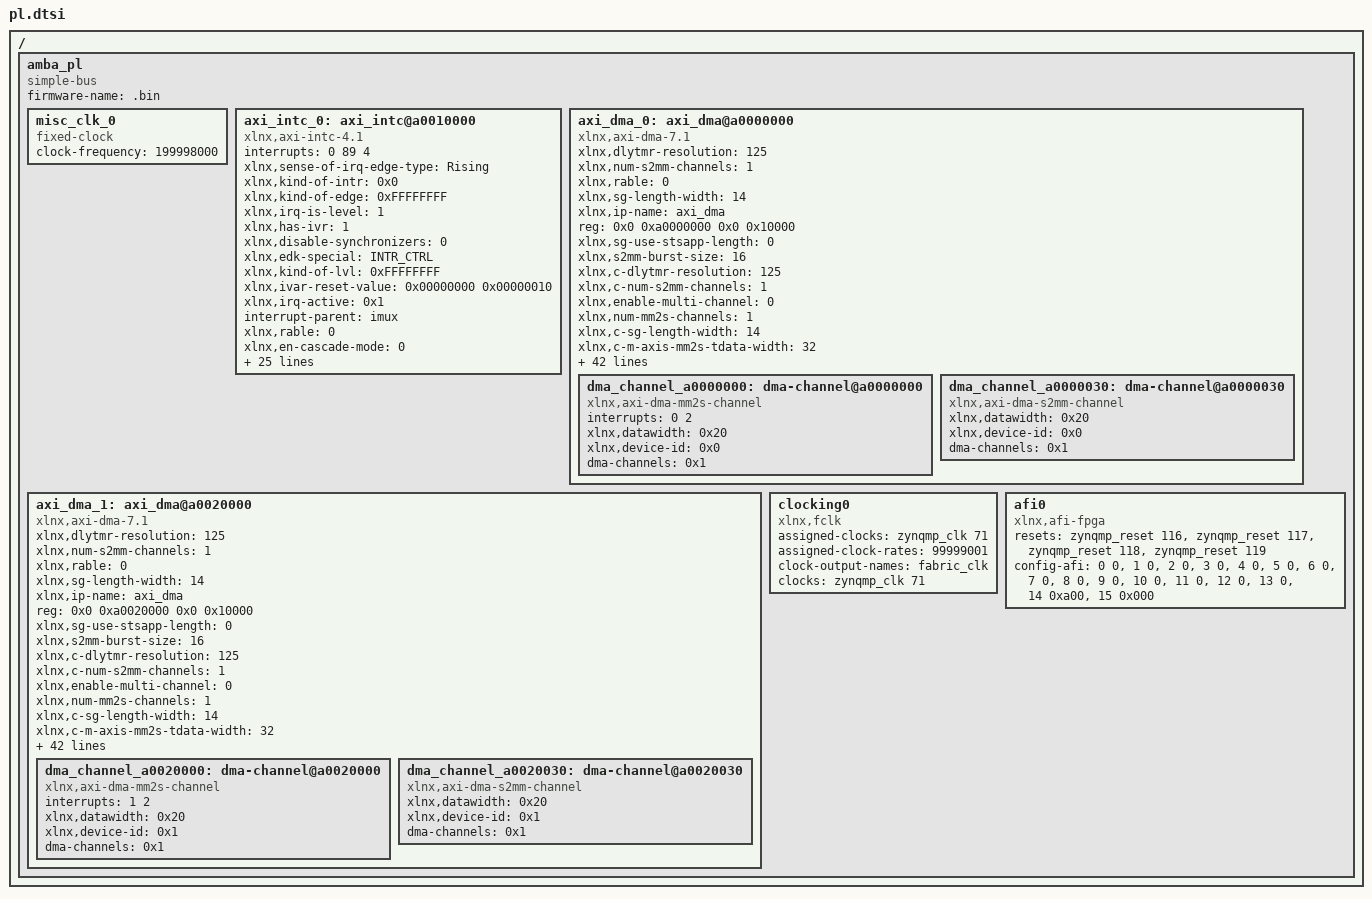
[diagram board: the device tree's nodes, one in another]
/ {
	amba_pl: amba_pl {
		ranges;
		compatible = "simple-bus";
		#address-cells = <2>;
		#size-cells = <2>;
		firmware-name = ".bin";
		misc_clk_0: misc_clk_0 {
			compatible = "fixed-clock";
			clock-frequency = <199998000>;
			#clock-cells = <0>;
		};
		axi_intc_0: axi_intc@a0010000 {
			#interrupt-cells = <2>;
			interrupts = < 0 89 4 >;
			xlnx,sense-of-irq-edge-type = "Rising";
			xlnx,kind-of-intr = <0x0>;
			xlnx,kind-of-edge = <0xFFFFFFFF>;
			xlnx,irq-is-level = <1>;
			xlnx,has-ivr = <1>;
			compatible = "xlnx,axi-intc-4.1" , "xlnx,xps-intc-1.00.a";
			xlnx,disable-synchronizers = <0>;
			xlnx,edk-special = "INTR_CTRL";
			xlnx,kind-of-lvl = <0xFFFFFFFF>;
			xlnx,ivar-reset-value = <0x00000000 0x00000010>;
			xlnx,irq-active = <0x1>;
			interrupt-parent = <&imux>;
			xlnx,rable = <0>;
			xlnx,en-cascade-mode = <0>;
			xlnx,ip-name = "axi_intc";
			xlnx,has-ilr = <0>;
			reg = <0x0 0xa0010000 0x0 0x10000>;
			xlnx,addr-width = <0x20>;
			clocks = <&misc_clk_0>;
			xlnx,s-axi-aclk-freq-mhz = <0xbebba30>;
			xlnx,num-sw-intr = <0>;
			xlnx,irq-connection = <1>;
			xlnx,num-intr-inputs = <0x2>;
			xlnx,has-sie = <1>;
			xlnx,has-cie = <1>;
			xlnx,enable-async = <0>;
			xlnx,num-sync-ff = <2>;
			xlnx,mb-clk-not-connected = <1>;
			xlnx,has-ipr = <1>;
			xlnx,edk-iptype = "PERIPHERAL";
			xlnx,sense-of-irq-level-type = "Active_High";
			xlnx,cascade-master = <0>;
			xlnx,processor-clk-freq-mhz = <100>;
			status = "okay";
			xlnx,is-fast = <0x0>;
			clock-names = "s_axi_aclk";
			xlnx,has-fast = <0>;
			xlnx,ivar-rst-val = <0x0000000000000010>;
			interrupt-controller;
			interrupt-names = "irq";
			xlnx,async-intr = <0xFFFFFFFC>;
			xlnx,name = "axi_intc_0";
		};
		axi_dma_0: axi_dma@a0000000 {
			xlnx,dlytmr-resolution = <125>;
			xlnx,num-s2mm-channels = <1>;
			xlnx,rable = <0>;
			xlnx,sg-length-width = <14>;
			xlnx,ip-name = "axi_dma";
			reg = <0x0 0xa0000000 0x0 0x10000>;
			xlnx,sg-use-stsapp-length = <0>;
			xlnx,s2mm-burst-size = <16>;
			xlnx,c-dlytmr-resolution = <125>;
			xlnx,c-num-s2mm-channels = <1>;
			xlnx,enable-multi-channel = <0>;
			xlnx,num-mm2s-channels = <1>;
			xlnx,c-sg-length-width = <14>;
			interrupt-names = "mm2s_introut";
			compatible = "xlnx,axi-dma-7.1" , "xlnx,axi-dma-1.00.a";
			xlnx,c-m-axis-mm2s-tdata-width = <32>;
			xlnx,c-sg-use-stsapp-length = <0>;
			xlnx,c-s2mm-burst-size = <16>;
			xlnx,mm2s-burst-size = <16>;
			xlnx,c-enable-multi-channel = <0>;
			xlnx,c-num-mm2s-channels = <1>;
			interrupt-parent = <&axi_intc_0>;
			xlnx,include-s2mm-dre = <0>;
			xlnx,include-sg;
			xlnx,c-mm2s-burst-size = <16>;
			status = "okay";
			xlnx,c-include-s2mm-dre = <0>;
			xlnx,include-mm2s-dre = <0>;
			xlnx,name = "axi_dma_0";
			interrupts = < 0 2 >;
			xlnx,c-include-sg = <1>;
			xlnx,c-m-axi-s2mm-data-width = <32>;
			xlnx,include-s2mm-sf = <1>;
			xlnx,c-include-mm2s-dre = <0>;
			xlnx,include-s2mm = <1>;
			clocks = <&misc_clk_0>, <&misc_clk_0>, <&misc_clk_0>, <&misc_clk_0>;
			xlnx,addrwidth = <0x20>;
			xlnx,c-m-axi-mm2s-data-width = <32>;
			xlnx,edk-iptype = "PERIPHERAL";
			xlnx,c-include-s2mm-sf = <1>;
			xlnx,include-mm2s-sf = <1>;
			clock-names = "m_axi_mm2s_aclk" , "m_axi_s2mm_aclk" , "m_axi_sg_aclk" , "s_axi_lite_aclk";
			xlnx,c-include-s2mm = <1>;
			xlnx,c-addr-width = <32>;
			xlnx,c-single-interface = <0>;
			xlnx,include-mm2s = <1>;
			xlnx,c-s-axis-s2mm-tdata-width = <32>;
			xlnx,s2mm-data-width = <0x20>;
			xlnx,c-include-mm2s-sf = <1>;
			xlnx,prmry-is-aclk-async = <0>;
			xlnx,sg-include-stscntrl-strm;
			xlnx,c-include-mm2s = <1>;
			xlnx,increase-throughput = <0>;
			xlnx,micro-dma = <0>;
			xlnx,mm2s-data-width = <0x20>;
			xlnx,c-prmry-is-aclk-async = <0>;
			xlnx,c-sg-include-stscntrl-strm = <1>;
			xlnx,c-increase-throughput = <0>;
			xlnx,c-micro-dma = <0>;
			dma_channel_a0000000: dma-channel@a0000000 {
				interrupts = <0 2>;
				xlnx,datawidth = <0x20>;
				xlnx,device-id = <0x0>;
				compatible = "xlnx,axi-dma-mm2s-channel";
				dma-channels = <0x1>;
			};
			dma_channel_a0000030: dma-channel@a0000030 {
				xlnx,datawidth = <0x20>;
				xlnx,device-id = <0x0>;
				compatible = "xlnx,axi-dma-s2mm-channel";
				dma-channels = <0x1>;
			};
		};
		axi_dma_1: axi_dma@a0020000 {
			xlnx,dlytmr-resolution = <125>;
			xlnx,num-s2mm-channels = <1>;
			xlnx,rable = <0>;
			xlnx,sg-length-width = <14>;
			xlnx,ip-name = "axi_dma";
			reg = <0x0 0xa0020000 0x0 0x10000>;
			xlnx,sg-use-stsapp-length = <0>;
			xlnx,s2mm-burst-size = <16>;
			xlnx,c-dlytmr-resolution = <125>;
			xlnx,c-num-s2mm-channels = <1>;
			xlnx,enable-multi-channel = <0>;
			xlnx,num-mm2s-channels = <1>;
			xlnx,c-sg-length-width = <14>;
			interrupt-names = "mm2s_introut";
			compatible = "xlnx,axi-dma-7.1" , "xlnx,axi-dma-1.00.a";
			xlnx,c-m-axis-mm2s-tdata-width = <32>;
			xlnx,c-sg-use-stsapp-length = <0>;
			xlnx,c-s2mm-burst-size = <16>;
			xlnx,mm2s-burst-size = <16>;
			xlnx,c-enable-multi-channel = <0>;
			xlnx,c-num-mm2s-channels = <1>;
			interrupt-parent = <&axi_intc_0>;
			xlnx,include-s2mm-dre = <0>;
			xlnx,include-sg;
			xlnx,c-mm2s-burst-size = <16>;
			status = "okay";
			xlnx,c-include-s2mm-dre = <0>;
			xlnx,include-mm2s-dre = <0>;
			xlnx,name = "axi_dma_1";
			interrupts = < 1 2 >;
			xlnx,c-include-sg = <1>;
			xlnx,c-m-axi-s2mm-data-width = <32>;
			xlnx,include-s2mm-sf = <1>;
			xlnx,c-include-mm2s-dre = <0>;
			xlnx,include-s2mm = <1>;
			clocks = <&misc_clk_0>, <&misc_clk_0>, <&misc_clk_0>, <&misc_clk_0>;
			xlnx,addrwidth = <0x20>;
			xlnx,c-m-axi-mm2s-data-width = <32>;
			xlnx,edk-iptype = "PERIPHERAL";
			xlnx,c-include-s2mm-sf = <1>;
			xlnx,include-mm2s-sf = <1>;
			clock-names = "m_axi_mm2s_aclk" , "m_axi_s2mm_aclk" , "m_axi_sg_aclk" , "s_axi_lite_aclk";
			xlnx,c-include-s2mm = <1>;
			xlnx,c-addr-width = <32>;
			xlnx,c-single-interface = <0>;
			xlnx,include-mm2s = <1>;
			xlnx,c-s-axis-s2mm-tdata-width = <32>;
			xlnx,s2mm-data-width = <0x20>;
			xlnx,c-include-mm2s-sf = <1>;
			xlnx,prmry-is-aclk-async = <0>;
			xlnx,sg-include-stscntrl-strm;
			xlnx,c-include-mm2s = <1>;
			xlnx,increase-throughput = <0>;
			xlnx,micro-dma = <0>;
			xlnx,mm2s-data-width = <0x20>;
			xlnx,c-prmry-is-aclk-async = <0>;
			xlnx,c-sg-include-stscntrl-strm = <1>;
			xlnx,c-increase-throughput = <0>;
			xlnx,c-micro-dma = <0>;
			dma_channel_a0020000: dma-channel@a0020000 {
				interrupts = <1 2>;
				xlnx,datawidth = <0x20>;
				xlnx,device-id = <0x1>;
				compatible = "xlnx,axi-dma-mm2s-channel";
				dma-channels = <0x1>;
			};
			dma_channel_a0020030: dma-channel@a0020030 {
				xlnx,datawidth = <0x20>;
				xlnx,device-id = <0x1>;
				compatible = "xlnx,axi-dma-s2mm-channel";
				dma-channels = <0x1>;
			};
		};
		clocking0: clocking0 {
			compatible = "xlnx,fclk";
			assigned-clocks = <&zynqmp_clk 71>;
			assigned-clock-rates = <99999001>;
			#clock-cells = <0>;
			clock-output-names = "fabric_clk";
			clocks = <&zynqmp_clk 71>;
		};
		afi0: afi0 {
			status = "okay";
			compatible = "xlnx,afi-fpga";
			resets = <&zynqmp_reset 116>, <&zynqmp_reset 117>, <&zynqmp_reset 118>, <&zynqmp_reset 119>;
			config-afi = < 0 0>, <1 0>, <2 0>, <3 0>, <4 0>, <5 0>, <6 0>, <7 0>, <8 0>, <9 0>, <10 0>, <11 0>, <12 0>, <13 0>, <14 0xa00>, <15 0x000>;
		};
	};
};
